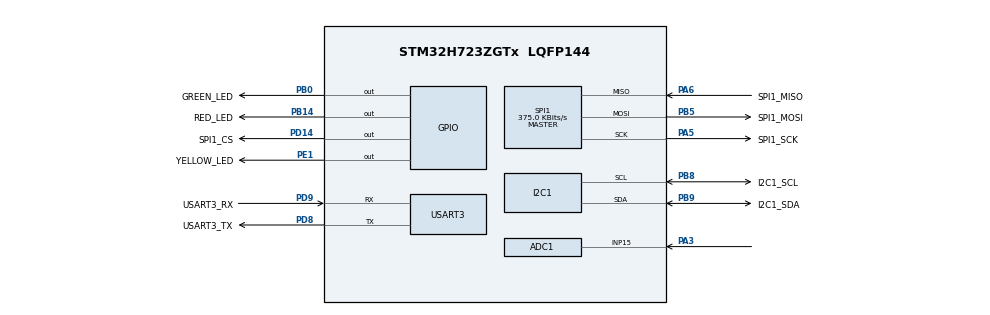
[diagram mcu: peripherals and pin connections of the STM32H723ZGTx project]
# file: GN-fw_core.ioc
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ADC1.Channel-0\#ChannelRegularConversion=ADC_CHANNEL_15
ADC1.ClockPrescaler=ADC_CLOCK_ASYNC_DIV1
ADC1.ConversionDataManagement=ADC_CONVERSIONDATA_DMA_CIRCULAR
ADC1.ExternalTrigConv=ADC_EXTERNALTRIG_T6_TRGO
ADC1.NbrOfConversionFlag=1
ADC1.OffsetNumber-0\#ChannelRegularConversion=ADC_OFFSET_NONE
ADC1.OffsetSignedSaturation-0\#ChannelRegularConversion=DISABLE
ADC1.Overrun=ADC_OVR_DATA_OVERWRITTEN
ADC1.Rank-0\#ChannelRegularConversion=1
ADC1.Resolution=ADC_RESOLUTION_12B
ADC1.SamplingTime-0\#ChannelRegularConversion=ADC_SAMPLETIME_64CYCLES_5
ADC1.master=1
CORTEX_M7.default_mode_Activation=1
Dma.ADC1.0.Direction=DMA_PERIPH_TO_MEMORY
Dma.ADC1.0.EventEnable=DISABLE
Dma.ADC1.0.FIFOMode=DMA_FIFOMODE_DISABLE
Dma.ADC1.0.Instance=DMA1_Stream0
Dma.ADC1.0.MemDataAlignment=DMA_MDATAALIGN_HALFWORD
Dma.ADC1.0.MemInc=DMA_MINC_ENABLE
Dma.ADC1.0.Mode=DMA_CIRCULAR
Dma.ADC1.0.PeriphDataAlignment=DMA_PDATAALIGN_HALFWORD
Dma.ADC1.0.PeriphInc=DMA_PINC_DISABLE
Dma.ADC1.0.Polarity=HAL_DMAMUX_REQ_GEN_RISING
Dma.ADC1.0.Priority=DMA_PRIORITY_HIGH
Dma.ADC1.0.RequestNumber=1
Dma.ADC1.0.SignalID=NONE
Dma.ADC1.0.SyncEnable=DISABLE
Dma.ADC1.0.SyncPolarity=HAL_DMAMUX_SYNC_NO_EVENT
Dma.ADC1.0.SyncRequestNumber=1
Dma.ADC1.0.SyncSignalID=NONE
Dma.Request0=ADC1
FATFS._FS_NORTC=1
FATFS._NORTC_MDAY=29
FATFS._NORTC_MON=1
FATFS._NORTC_YEAR=2026
I2C1.Timing=0x10B0DCFB
Mcu.Family=STM32H7
Mcu.Name=STM32H723ZGTx
Mcu.Package=LQFP144
NVIC.DMA1_Stream0_IRQn=true\:0\:0\:false\:false\:true\:false\:true\:true
NVIC.PriorityGroup=NVIC_PRIORITYGROUP_4
PA3.Signal=ADCx_INP15
PA5.GPIO_Label=SPI1_SCK
PA5.Mode=Full_Duplex_Master
PA5.Signal=SPI1_SCK
PA6.GPIO_Label=SPI1_MISO
PA6.Mode=Full_Duplex_Master
PA6.Signal=SPI1_MISO
PB0.GPIO_Label=GREEN_LED
PB0.Signal=GPIO_Output
PB14.GPIO_Label=RED_LED
PB14.Signal=GPIO_Output
PB5.GPIO_Label=SPI1_MOSI
PB5.Mode=Full_Duplex_Master
PB5.Signal=SPI1_MOSI
PB8.GPIO_Label=I2C1_SCL
PB8.Mode=I2C
PB8.Signal=I2C1_SCL
PB9.GPIO_Label=I2C1_SDA
PB9.Mode=I2C
PB9.Signal=I2C1_SDA
PD14.GPIO_Label=SPI1_CS
PD14.Signal=GPIO_Output
PD8.GPIO_Label=USART3_TX
PD8.Mode=Asynchronous
PD8.Signal=USART3_TX
PD9.GPIO_Label=USART3_RX
PD9.Mode=Asynchronous
PD9.Signal=USART3_RX
PE1.GPIO_Label=YELLOW_LED
PE1.Signal=GPIO_Output
ProjectManager.HeapSize=0x200
ProjectManager.StackSize=0x400
ProjectManager.TargetToolchain=STM32CubeIDE
RCC.ADCFreq_Value=48000000
RCC.APB1Freq_Value=96000000
RCC.APB2Freq_Value=96000000
RCC.APB3Freq_Value=96000000
RCC.APB4Freq_Value=96000000
RCC.CortexFreq_Value=192000000
RCC.D1PPRE=RCC_APB3_DIV2
RCC.D2PPRE1=RCC_APB1_DIV2
RCC.D2PPRE2=RCC_APB2_DIV2
RCC.D3PPRE=RCC_APB4_DIV2
RCC.DIVM1=4
RCC.DIVM2=4
RCC.DIVN1=12
RCC.DIVN2=12
RCC.DIVP1=1
RCC.DIVP2=4
RCC.HCLKFreq_Value=192000000
RCC.PLL2FRACN=0
RCC.PLL3FRACN=0
RCC.PLLFRACN=0
RCC.SYSCLKFreq_VALUE=192000000
RCC.SYSCLKSource=RCC_SYSCLKSOURCE_PLLCLK
RCC.USBFreq_Value=96000000
SH.ADCx_INP15.0=ADC1_INP15,IN15-Single-Ended
SPI1.BaudRatePrescaler=SPI_BAUDRATEPRESCALER_256
SPI1.CalculateBaudRate=375.0 KBits/s
SPI1.DataSize=SPI_DATASIZE_8BIT
SPI1.Direction=SPI_DIRECTION_2LINES
SPI1.Mode=SPI_MODE_MASTER
SPI1.VirtualType=VM_MASTER
TIM6.Period=959
TIM6.TIM_MasterOutputTrigger=TIM_TRGO_UPDATE
USART3.VirtualMode-Asynchronous=VM_ASYNC
VP_FATFS_VS_Generic.Mode=User_defined
VP_MEMORYMAP_VS_MEMORYMAP.Mode=CurAppReg
VP_TIM6_VS_ClockSourceINT.Mode=Enable_Timer
board=custom

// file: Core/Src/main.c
/* USER CODE BEGIN Header */
/**
  ******************************************************************************
  * @file           : main.c
  * @brief          : Main program body
  ******************************************************************************
  * @attention
  *
  * Copyright (c) 2026 STMicroelectronics.
  * All rights reserved.
  *
  * This software is licensed under terms that can be found in the LICENSE file
  * in the root directory of this software component.
  * If no LICENSE file comes with this software, it is provided AS-IS.
  *
  ******************************************************************************
  */
/* USER CODE END Header */
#include "main.h"
#include "adc.h"
#include "dma.h"
#include "fatfs.h"
#include "i2c.h"
#include "spi.h"
#include "tim.h"
#include "usart.h"
#include "gpio.h"

/* USER CODE BEGIN Includes */
#include "app_boot.h"
#include "app_run.h"
#include "app_panic.h"
/* USER CODE END Includes */

/* USER CODE BEGIN PD */
#define TAG "MAIN"
/* USER CODE END PD */

void SystemClock_Config(void);
static void MPU_Config(void);

int main(void)
{

  /* USER CODE BEGIN 1 */
  //SCB_DisableDCache();
  /* USER CODE END 1 */

  /* MPU Configuration--------------------------------------------------------*/
  MPU_Config();

  /* MCU Configuration--------------------------------------------------------*/

  /* Reset of all peripherals, Initializes the Flash interface and the Systick. */
  HAL_Init();

  /* Configure the system clock */
  SystemClock_Config();

  /* Initialize all configured peripherals */
  MX_GPIO_Init();
  MX_DMA_Init();
  MX_I2C1_Init();
  MX_SPI1_Init();
  MX_USART3_UART_Init();
  MX_FATFS_Init();
  MX_ADC1_Init();
  MX_TIM6_Init();
  /* USER CODE BEGIN 2 */
  app_boot();
  /* USER CODE END 2 */

  /* Infinite loop */
  /* USER CODE BEGIN WHILE */
  app_run_forever();
    /* USER CODE END WHILE */

}

void SystemClock_Config(void)
{
  RCC_OscInitTypeDef RCC_OscInitStruct = {0};
  RCC_ClkInitTypeDef RCC_ClkInitStruct = {0};

  /** Supply configuration update enable
  */
  HAL_PWREx_ConfigSupply(PWR_LDO_SUPPLY);

  /** Configure the main internal regulator output voltage
  */
  __HAL_PWR_VOLTAGESCALING_CONFIG(PWR_REGULATOR_VOLTAGE_SCALE1);

  while(!__HAL_PWR_GET_FLAG(PWR_FLAG_VOSRDY)) {}

  /** Initializes the RCC Oscillators according to the specified parameters
  * in the RCC_OscInitTypeDef structure.
  */
  RCC_OscInitStruct.OscillatorType = RCC_OSCILLATORTYPE_HSI;
  RCC_OscInitStruct.HSIState = RCC_HSI_DIV1;
  RCC_OscInitStruct.HSICalibrationValue = 64;
  RCC_OscInitStruct.PLL.PLLState = RCC_PLL_ON;
  RCC_OscInitStruct.PLL.PLLSource = RCC_PLLSOURCE_HSI;
  RCC_OscInitStruct.PLL.PLLM = 4;
  RCC_OscInitStruct.PLL.PLLN = 12;
  RCC_OscInitStruct.PLL.PLLP = 1;
  RCC_OscInitStruct.PLL.PLLQ = 2;
  RCC_OscInitStruct.PLL.PLLR = 2;
  RCC_OscInitStruct.PLL.PLLRGE = RCC_PLL1VCIRANGE_3;
  RCC_OscInitStruct.PLL.PLLVCOSEL = RCC_PLL1VCOWIDE;
  RCC_OscInitStruct.PLL.PLLFRACN = 0;
  if (HAL_RCC_OscConfig(&RCC_OscInitStruct) != HAL_OK)
  {
    Error_Handler();
  }

  /** Initializes the CPU, AHB and APB buses clocks
  */
  RCC_ClkInitStruct.ClockType = RCC_CLOCKTYPE_HCLK|RCC_CLOCKTYPE_SYSCLK
                              |RCC_CLOCKTYPE_PCLK1|RCC_CLOCKTYPE_PCLK2
                              |RCC_CLOCKTYPE_D3PCLK1|RCC_CLOCKTYPE_D1PCLK1;
  RCC_ClkInitStruct.SYSCLKSource = RCC_SYSCLKSOURCE_PLLCLK;
  RCC_ClkInitStruct.SYSCLKDivider = RCC_SYSCLK_DIV1;
  RCC_ClkInitStruct.AHBCLKDivider = RCC_HCLK_DIV1;
  RCC_ClkInitStruct.APB3CLKDivider = RCC_APB3_DIV2;
  RCC_ClkInitStruct.APB1CLKDivider = RCC_APB1_DIV2;
  RCC_ClkInitStruct.APB2CLKDivider = RCC_APB2_DIV2;
  RCC_ClkInitStruct.APB4CLKDivider = RCC_APB4_DIV2;

  if (HAL_RCC_ClockConfig(&RCC_ClkInitStruct, FLASH_LATENCY_2) != HAL_OK)
  {
    Error_Handler();
  }
}

 /* MPU Configuration */

void MPU_Config(void)
{
  MPU_Region_InitTypeDef MPU_InitStruct = {0};

  /* Disables the MPU */
  HAL_MPU_Disable();

  /** Initializes and configures the Region and the memory to be protected
  */
  MPU_InitStruct.Enable = MPU_REGION_ENABLE;
  MPU_InitStruct.Number = MPU_REGION_NUMBER0;
  MPU_InitStruct.BaseAddress = 0x0;
  MPU_InitStruct.Size = MPU_REGION_SIZE_4GB;
  MPU_InitStruct.SubRegionDisable = 0x87;
  MPU_InitStruct.TypeExtField = MPU_TEX_LEVEL0;
  MPU_InitStruct.AccessPermission = MPU_REGION_NO_ACCESS;
  MPU_InitStruct.DisableExec = MPU_INSTRUCTION_ACCESS_DISABLE;
  MPU_InitStruct.IsShareable = MPU_ACCESS_SHAREABLE;
  MPU_InitStruct.IsCacheable = MPU_ACCESS_NOT_CACHEABLE;
  MPU_InitStruct.IsBufferable = MPU_ACCESS_NOT_BUFFERABLE;

  HAL_MPU_ConfigRegion(&MPU_InitStruct);
  /* Enables the MPU */
  HAL_MPU_Enable(MPU_PRIVILEGED_DEFAULT);

}

void Error_Handler(void)
{
  /* USER CODE BEGIN Error_Handler_Debug */
  /* User can add his own implementation to report the HAL error return state */
    app_panic(APP_PANIC_HAL_ERROR);
  /* USER CODE END Error_Handler_Debug */
}
